# CY8C5488AXI_LP120 register map
File version: 0.1
Registers are 8-bit, read-write, no defined reset value unless marked. A register's access mark holds for its fields unless they carry their own. Offsets are from the block's base; [hi:lo] are bit positions; {n}, {i} and the like mark numbered series.

## I2C
Base 0x00000000
0x4000640B I2C_DATA
  [7:0] data — Read received data or write data to transmit.
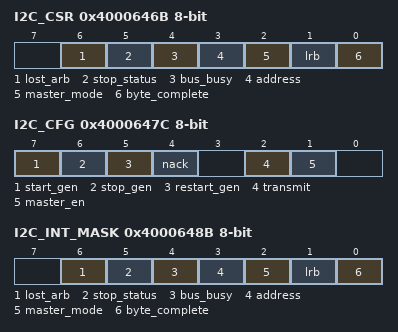
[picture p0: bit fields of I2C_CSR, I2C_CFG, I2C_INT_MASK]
0x4000646B I2C_CSR — I2C Status Register
  [6] lost_arb ro — If set, indicates arbitration was lost (multi-master and multi-master-slave modes).
  [5] stop_status ro — If set, indicates a Stop condition was detected on the bus.
  [4] bus_busy ro — If set, indicates the bus is busy. Data is currently being transmitted or received.
  [3] address ro — Address detection. If set, indicates that an address byte was sent.
  [2] master_mode ro — Indicates that a valid Start condition was generated and a hardware device is operating as bus master.
  [1] lrb ro — Last Received Bit. Indicates the state of the last received bit, which is the ACK/NAK received for the last byte transmitted. Cleared = ACK and set = NAK.
  [0] byte_complete ro — Transmit or receive status since the last read of this register. In Transmit mode this bit indicates that eight bits of data plus ACK/NAK have been transmitted since the last read. In Receive mode this bit indicates that eight bits of data have been received since the last read of this register.
0x4000647C I2C_CFG — I2C Configuration Register
  [7] start_gen — Set to 1 to generate a Start condition on the bus. This bit must be cleared by firmware before initiating the next transaction.
  [6] stop_gen — Set to 1 to generate a Stop condition on the bus. This bit must be cleared by firmware before initiating the next transaction.
  [5] restart_gen — Set to 1 to generate a Restart condition on the bus. This bit must be cleared by firmware after a Restart condition is generated.
  [4] nack — Set to 1 to NAK the next read byte. Clear to ACK next read byte. This bit must be cleared by firmware between bytes.
  [2] transmit — Set to 1 to set the current mode to transmit or clear to 0 to receive a byte of data. This bit must be cleared by firmware before starting the next transmit or receive transaction.
  [1] master_en — Set to 1 to enable the master functionality.
0x4000648B I2C_INT_MASK — I2C Interrupt Enable Mask
  [6] lost_arb — Enables interrupt from the corresponding bit in status register.
  [5] stop_status — Enables interrupt from the corresponding bit in status register.
  [4] bus_busy — Enables interrupt from the corresponding bit in status register.
  [3] address — Enables interrupt from the corresponding bit in status register.
  [2] master_mode — Enables interrupt from the corresponding bit in status register.
  [1] lrb — Enables interrupt from the corresponding bit in status register.
  [0] byte_complete — Enables interrupt from the corresponding bit in status register.

## USB — USBFS
Base 0x00000000
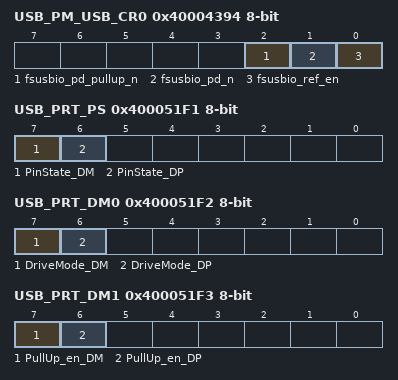
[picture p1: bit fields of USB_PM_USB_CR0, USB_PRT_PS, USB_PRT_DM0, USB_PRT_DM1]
0x40004394 USB_PM_USB_CR0 — USB Power Mode Control Register 0
  [2] fsusbio_pd_pullup_n, [1] fsusbio_pd_n, [0] fsusbio_ref_en
0x400043A5 USB_PM_ACT_CFG — Active Power Mode Configuration Register
0x400043B5 USB_PM_STBY_CFG — Standby Power Mode Configuration Register
0x400051F1 USB_PRT_PS — Port Pin State Register
  [7] PinState_DM ro, [6] PinState_DP ro
0x400051F2 USB_PRT_DM0 — Port Drive Mode Register
  [7] DriveMode_DM, [6] DriveMode_DP
0x400051F3 USB_PRT_DM1 — Port Drive Mode Register
  [7] PullUp_en_DM, [6] PullUp_en_DP
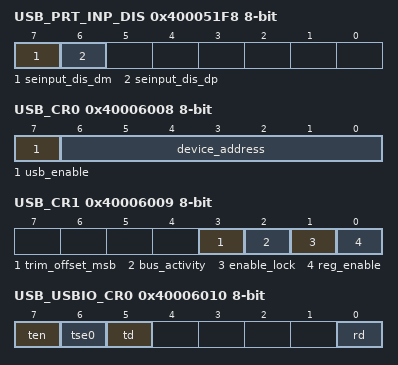
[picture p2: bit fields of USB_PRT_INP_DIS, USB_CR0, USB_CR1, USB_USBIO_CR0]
0x400051F8 USB_PRT_INP_DIS — Input buffer disable override
  [7] seinput_dis_dm, [6] seinput_dis_dp
0x40006000 USB_EP0_DR0 — bmRequestType
0x40006001 USB_EP0_DR1 — bRequest
0x40006002 USB_EP0_DR2 — wValueLo
0x40006003 USB_EP0_DR3 — wValueHi
0x40006004 USB_EP0_DR4 — wIndexLo
0x40006005 USB_EP0_DR5 — wIndexHi
0x40006006 USB_EP0_DR6 — lengthLo
0x40006007 USB_EP0_DR7 — lengthHi
0x40006008 USB_CR0 — USB Control Register 0
  [7] usb_enable, [6:0] device_address ro
0x40006009 USB_CR1 — USB Control Register 1
  [3] trim_offset_msb, [2] bus_activity, [1] enable_lock, [0] reg_enable
{0x40005FFE+0x10*i} USB_SIE_EP{i}_CR0 (i=1..8) — The Endpoint{i} Control Register
0x40006010 USB_USBIO_CR0 — USBIO Control Register 0
  [7] ten, [6] tse0, [5] td, [0] rd ro
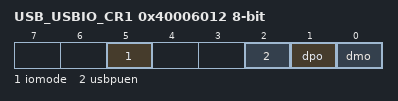
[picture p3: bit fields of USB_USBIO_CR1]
0x40006012 USB_USBIO_CR1 — USBIO Control Register 1
  [5] iomode, [2] usbpuen, [1] dpo ro, [0] dmo ro
0x4000608C USB_BUF_SIZE — Dedicated Endpoint Buffer Size Register
0x4000608E USB_EP_ACTIVE — Endpoint Active Indication Register
0x4000608F USB_EP_TYPE — Endpoint Type (IN/OUT) Indication
0x4000609D USB_USB_CLK_EN — USB Block Clock Enable Register
